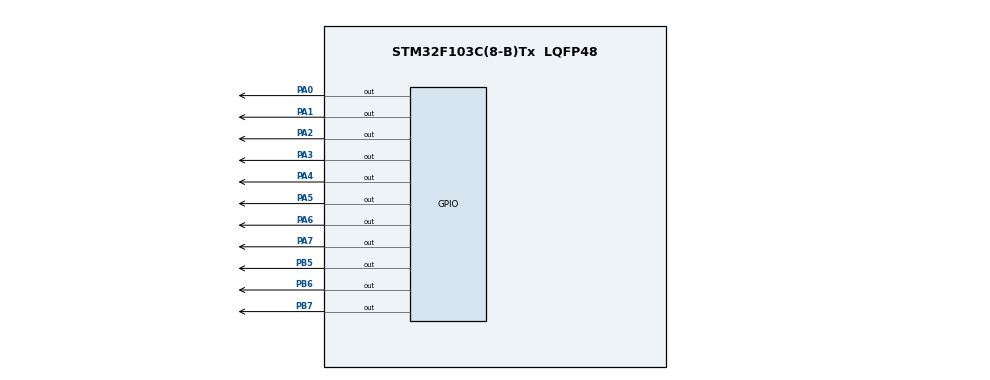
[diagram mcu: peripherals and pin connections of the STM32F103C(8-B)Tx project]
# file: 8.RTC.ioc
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Mcu.Family=STM32F1
Mcu.Name=STM32F103C(8-B)Tx
Mcu.Package=LQFP48
NVIC.PriorityGroup=NVIC_PRIORITYGROUP_4
PA0-WKUP.Signal=GPIO_Output
PA1.Signal=GPIO_Output
PA13.Mode=Serial_Wire
PA13.Signal=SYS_JTMS-SWDIO
PA14.Mode=Serial_Wire
PA14.Signal=SYS_JTCK-SWCLK
PA2.Signal=GPIO_Output
PA3.Signal=GPIO_Output
PA4.Signal=GPIO_Output
PA5.Signal=GPIO_Output
PA6.Signal=GPIO_Output
PA7.Signal=GPIO_Output
PB5.Signal=GPIO_Output
PB6.Signal=GPIO_Output
PB7.Signal=GPIO_Output
PC14-OSC32_IN.Mode=LSE-External-Oscillator
PC14-OSC32_IN.Signal=RCC_OSC32_IN
PC15-OSC32_OUT.Mode=LSE-External-Oscillator
PC15-OSC32_OUT.Signal=RCC_OSC32_OUT
PD0-OSC_IN.Mode=HSE-External-Oscillator
PD0-OSC_IN.Signal=RCC_OSC_IN
PD1-OSC_OUT.Mode=HSE-External-Oscillator
PD1-OSC_OUT.Signal=RCC_OSC_OUT
ProjectManager.HeapSize=0x200
ProjectManager.StackSize=0x400
ProjectManager.TargetToolchain=EWARM V8.32
RCC.APB1Freq_Value=8000000
RCC.APB2Freq_Value=8000000
RCC.RTCClockSelection=RCC_RTCCLKSOURCE_LSE
RCC.SYSCLKSource=RCC_SYSCLKSOURCE_HSE
RTC.Date=28
RTC.Format=RTC_FORMAT_BIN
RTC.Hours=14
RTC.Minutes=43
RTC.Month=RTC_MONTH_SEPTEMBER
VP_RTC_VS_RTC_Activate.Mode=RTC_Enabled
VP_RTC_VS_RTC_Calendar.Mode=RTC_Calendar
board=custom

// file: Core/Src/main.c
/* USER CODE BEGIN Header */
/**
  ******************************************************************************
  * @file           : main.c
  * @brief          : Main program body
  ******************************************************************************
  * @attention
  *
  * Copyright (c) 2024 STMicroelectronics.
  * All rights reserved.
  *
  * This software is licensed under terms that can be found in the LICENSE file
  * in the root directory of this software component.
  * If no LICENSE file comes with this software, it is provided AS-IS.
  *
  ******************************************************************************
  */
/* USER CODE END Header */
#include "main.h"

/* USER CODE BEGIN Includes */

#include "LCD/lcd.h"
#include "stdio.h"

/* USER CODE END Includes */

RTC_HandleTypeDef hrtc;

/* USER CODE BEGIN PV */

char Time[17];
RTC_TimeTypeDef set_time;

/* USER CODE END PV */

void SystemClock_Config(void);
static void MX_GPIO_Init(void);
static void MX_RTC_Init(void);

int main(void)
{

  /* MCU Configuration--------------------------------------------------------*/

  /* Reset of all peripherals, Initializes the Flash interface and the Systick. */
  HAL_Init();

  /* Configure the system clock */
  SystemClock_Config();

  /* Initialize all configured peripherals */
  MX_GPIO_Init();
  MX_RTC_Init();

  /* Infinite loop */
  /* USER CODE BEGIN WHILE */

  set_time.Hours=18;
  set_time.Minutes=00;
  set_time.Seconds=00;

  HAL_RTC_SetTime(&hrtc,&set_time,RTC_FORMAT_BIN);

  lcd_init();
  lcd_clear();
  lcd_gotoxy(0,0);
  lcd_puts("Hello RTC...");
  HAL_Delay(2000);
  lcd_clear();

  while (1)
  {
    /* USER CODE END WHILE */
    HAL_RTC_GetTime(&hrtc,&set_time,RTC_FORMAT_BIN);
    sprintf(Time,"%02d:%02d:%02d",set_time.Hours,set_time.Minutes, set_time.Seconds);
    lcd_gotoxy(0,0);
    lcd_puts(Time);

  }
}

void SystemClock_Config(void)
{
  RCC_OscInitTypeDef RCC_OscInitStruct = {0};
  RCC_ClkInitTypeDef RCC_ClkInitStruct = {0};
  RCC_PeriphCLKInitTypeDef PeriphClkInit = {0};

  /** Initializes the RCC Oscillators according to the specified parameters
  * in the RCC_OscInitTypeDef structure.
  */
  RCC_OscInitStruct.OscillatorType = RCC_OSCILLATORTYPE_HSE|RCC_OSCILLATORTYPE_LSE;
  RCC_OscInitStruct.HSEState = RCC_HSE_ON;
  RCC_OscInitStruct.LSEState = RCC_LSE_ON;
  RCC_OscInitStruct.PLL.PLLState = RCC_PLL_NONE;
  if (HAL_RCC_OscConfig(&RCC_OscInitStruct) != HAL_OK)
  {
    Error_Handler();
  }

  /** Initializes the CPU, AHB and APB buses clocks
  */
  RCC_ClkInitStruct.ClockType = RCC_CLOCKTYPE_HCLK|RCC_CLOCKTYPE_SYSCLK
                              |RCC_CLOCKTYPE_PCLK1|RCC_CLOCKTYPE_PCLK2;
  RCC_ClkInitStruct.SYSCLKSource = RCC_SYSCLKSOURCE_HSE;
  RCC_ClkInitStruct.AHBCLKDivider = RCC_SYSCLK_DIV1;
  RCC_ClkInitStruct.APB1CLKDivider = RCC_HCLK_DIV1;
  RCC_ClkInitStruct.APB2CLKDivider = RCC_HCLK_DIV1;

  if (HAL_RCC_ClockConfig(&RCC_ClkInitStruct, FLASH_LATENCY_0) != HAL_OK)
  {
    Error_Handler();
  }
  PeriphClkInit.PeriphClockSelection = RCC_PERIPHCLK_RTC;
  PeriphClkInit.RTCClockSelection = RCC_RTCCLKSOURCE_LSE;
  if (HAL_RCCEx_PeriphCLKConfig(&PeriphClkInit) != HAL_OK)
  {
    Error_Handler();
  }
}

static void MX_RTC_Init(void)
{

  /** Initialize RTC Only
  */
  hrtc.Instance = RTC;
  hrtc.Init.AsynchPrediv = RTC_AUTO_1_SECOND;
  hrtc.Init.OutPut = RTC_OUTPUTSOURCE_ALARM;
  if (HAL_RTC_Init(&hrtc) != HAL_OK)
  {
    Error_Handler();
  }

  /** Initialize RTC and set the Time and Date
  */

}

static void MX_GPIO_Init(void)
{
  GPIO_InitTypeDef GPIO_InitStruct = {0};

  /* GPIO Ports Clock Enable */
  __HAL_RCC_GPIOC_CLK_ENABLE();
  __HAL_RCC_GPIOD_CLK_ENABLE();
  __HAL_RCC_GPIOA_CLK_ENABLE();
  __HAL_RCC_GPIOB_CLK_ENABLE();

  /*Configure GPIO pin Output Level */
  HAL_GPIO_WritePin(GPIOA, GPIO_PIN_0|GPIO_PIN_1|GPIO_PIN_2|GPIO_PIN_3
                          |GPIO_PIN_4|GPIO_PIN_5|GPIO_PIN_6|GPIO_PIN_7, GPIO_PIN_RESET);

  /*Configure GPIO pin Output Level */
  HAL_GPIO_WritePin(GPIOB, GPIO_PIN_5|GPIO_PIN_6|GPIO_PIN_7, GPIO_PIN_RESET);

  /*Configure GPIO pins : PA0 PA1 PA2 PA3
                           PA4 PA5 PA6 PA7 */
  GPIO_InitStruct.Pin = GPIO_PIN_0|GPIO_PIN_1|GPIO_PIN_2|GPIO_PIN_3
                          |GPIO_PIN_4|GPIO_PIN_5|GPIO_PIN_6|GPIO_PIN_7;
  GPIO_InitStruct.Mode = GPIO_MODE_OUTPUT_PP;
  GPIO_InitStruct.Pull = GPIO_NOPULL;
  GPIO_InitStruct.Speed = GPIO_SPEED_FREQ_LOW;
  HAL_GPIO_Init(GPIOA, &GPIO_InitStruct);

  /*Configure GPIO pins : PB5 PB6 PB7 */
  GPIO_InitStruct.Pin = GPIO_PIN_5|GPIO_PIN_6|GPIO_PIN_7;
  GPIO_InitStruct.Mode = GPIO_MODE_OUTPUT_PP;
  GPIO_InitStruct.Pull = GPIO_NOPULL;
  GPIO_InitStruct.Speed = GPIO_SPEED_FREQ_LOW;
  HAL_GPIO_Init(GPIOB, &GPIO_InitStruct);

}

void Error_Handler(void)
{
  __disable_irq();
  while (1)
  {
  }
}
